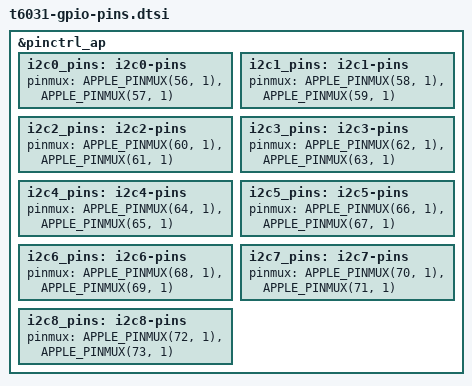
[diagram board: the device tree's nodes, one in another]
// SPDX-License-Identifier: GPL-2.0+ OR MIT
/*
 * GPIO pin mappings for Apple T6031/T6032/T6034 SoCs.
 *
 * Copyright The Asahi Linux Contributors
 */

&pinctrl_ap {
	i2c0_pins: i2c0-pins {
		pinmux = <APPLE_PINMUX(56, 1)>,
			<APPLE_PINMUX(57, 1)>;
	};

	i2c1_pins: i2c1-pins {
		pinmux = <APPLE_PINMUX(58, 1)>,
			<APPLE_PINMUX(59, 1)>;
	};

	i2c2_pins: i2c2-pins {
		pinmux = <APPLE_PINMUX(60, 1)>,
			<APPLE_PINMUX(61, 1)>;
	};

	i2c3_pins: i2c3-pins {
		pinmux = <APPLE_PINMUX(62, 1)>,
			<APPLE_PINMUX(63, 1)>;
	};

	i2c4_pins: i2c4-pins {
		pinmux = <APPLE_PINMUX(64, 1)>,
			<APPLE_PINMUX(65, 1)>;
	};

	i2c5_pins: i2c5-pins {
		pinmux = <APPLE_PINMUX(66, 1)>,
			<APPLE_PINMUX(67, 1)>;
	};

	i2c6_pins: i2c6-pins {
		pinmux = <APPLE_PINMUX(68, 1)>,
			<APPLE_PINMUX(69, 1)>;
	};

	i2c7_pins: i2c7-pins {
		pinmux = <APPLE_PINMUX(70, 1)>,
			<APPLE_PINMUX(71, 1)>;
	};

	i2c8_pins: i2c8-pins {
		pinmux = <APPLE_PINMUX(72, 1)>,
			<APPLE_PINMUX(73, 1)>;
	};
};
